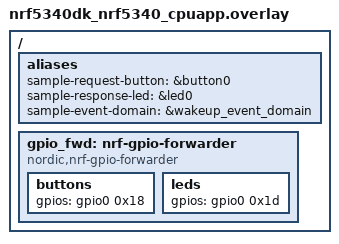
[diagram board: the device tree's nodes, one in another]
/*
 * Copyright (c) 2025 Nordic Semiconductor ASA
 *
 * SPDX-License-Identifier: Apache-2.0
 */

/ {
	aliases {
		sample-request-button = &button0;
		sample-response-led = &led0;
		sample-event-domain = &wakeup_event_domain;
	};

	gpio_fwd: nrf-gpio-forwarder {
		compatible = "nordic,nrf-gpio-forwarder";
		status = "okay";

		buttons {
			gpios = <&gpio0 0x18 0>;
		};

		leds {
			gpios = <&gpio0 0x1d 0>;
		};
	};
};
